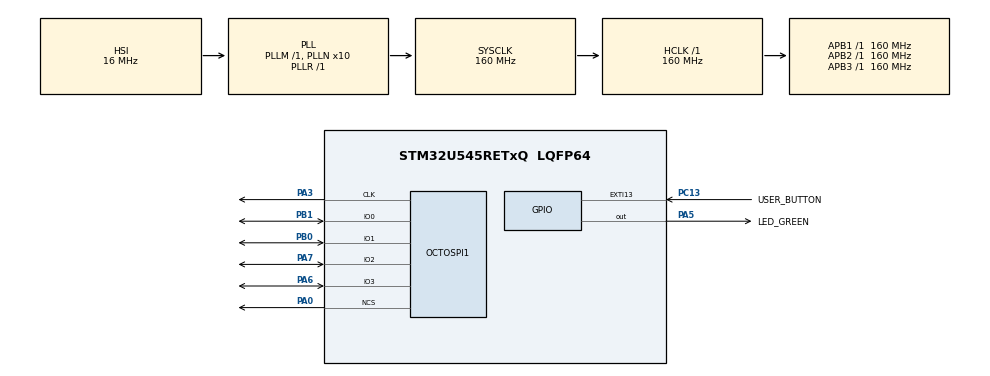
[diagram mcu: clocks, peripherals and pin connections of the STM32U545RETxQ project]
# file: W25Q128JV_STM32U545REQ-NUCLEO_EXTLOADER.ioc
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CORTEX_M33_NS.userName=CORTEX_M33
Mcu.Family=STM32U5
Mcu.Name=STM32U545RETxQ
Mcu.Package=LQFP64
NVIC.PriorityGroup=NVIC_PRIORITYGROUP_4
OCTOSPI1.ChipSelectBoundary=0
OCTOSPI1.ChipSelectHighTime=1
OCTOSPI1.ClockPrescaler=159
OCTOSPI1.DelayHoldQuarterCycle=HAL_OSPI_DHQC_DISABLE
OCTOSPI1.DeviceSize=24
OCTOSPI1.FifoThreshold=1
PA0.Mode=quad_mode
PA0.Signal=OCTOSPI1_NCS
PA13\ (JTMS/SWDIO).Mode=Serial_Wire
PA13\ (JTMS/SWDIO).Signal=DEBUG_JTMS-SWDIO
PA14\ (JTCK/SWCLK).Mode=Serial_Wire
PA14\ (JTCK/SWCLK).Signal=DEBUG_JTCK-SWCLK
PA3.Mode=quad_mode
PA3.Signal=OCTOSPI1_CLK
PA5.GPIO_Label=LED_GREEN
PA5.GPIO_PuPd=GPIO_PULLUP
PA5.GPIO_Speed=GPIO_SPEED_FREQ_HIGH
PA5.Signal=GPIO_Output
PA6.Mode=quad_mode
PA6.Signal=OCTOSPI1_IO3
PA7.Mode=quad_mode
PA7.Signal=OCTOSPI1_IO2
PB0.Mode=quad_mode
PB0.Signal=OCTOSPI1_IO1
PB1.Mode=quad_mode
PB1.Signal=OCTOSPI1_IO0
PC13.GPIO_Label=USER_BUTTON
PC13.GPIO_ModeDefaultEXTI=GPIO_MODE_IT_FALLING
PC13.Signal=GPXTI13
PC14-OSC32_IN\ (PC14).Mode=LSE-External-Oscillator
PC14-OSC32_IN\ (PC14).Signal=RCC_OSC32_IN
PC15-OSC32_OUT\ (PC15).Mode=LSE-External-Oscillator
PC15-OSC32_OUT\ (PC15).Signal=RCC_OSC32_OUT
PWR.PowerMode=PWR_SMPS_SUPPLY
ProjectManager.HeapSize=0x200
ProjectManager.StackSize=0x400
ProjectManager.TargetToolchain=STM32CubeIDE
RCC.ADCCLockSelection=RCC_ADCDACCLKSOURCE_PLL2
RCC.ADCFreq_Value=160000000
RCC.AHBFreq_Value=160000000
RCC.APB1Freq_Value=160000000
RCC.APB1TimFreq_Value=160000000
RCC.APB2Freq_Value=160000000
RCC.APB2TimFreq_Value=160000000
RCC.APB3Freq_Value=160000000
RCC.CortexFreq_Value=160000000
RCC.DACCLockSelectionVirtual=RCC_DAC1CLKSOURCE_LSI
RCC.DACCLockSelectionVirtualString=RCC_DAC1CLKSOURCE_LSI
RCC.EPOD_VALUE=16000000
RCC.HCLKFreq_Value=160000000
RCC.HSE_VALUE=16000000
RCC.HSI48_VALUE=48000000
RCC.HSI_VALUE=16000000
RCC.LSIDIV_VALUE=32000
RCC.MSI_VALUE=4000000
RCC.OCTOSPIMCLockSelection=RCC_OSPICLKSOURCE_PLL1
RCC.PLL1Q=1
RCC.PLL1R=1
RCC.PLL2FRACN=0
RCC.PLL2N=10
RCC.PLL2R=1
RCC.PLL2Source=RCC_PLLSOURCE_HSI
RCC.PLL3FRACN=0
RCC.PLL3M=12
RCC.PLL3Source=RCC_PLLSOURCE_HSI
RCC.PLLFRACN=0
RCC.PLLN=10
RCC.PLLSourceVirtual=RCC_PLLSOURCE_HSI
RCC.SYSCLKFreq_VALUE=160000000
RCC.SYSCLKSource=RCC_SYSCLKSOURCE_PLLCLK
RCC.USBFreq_Value=48000000
RCC.VCOOutputFreq_Value=160000000
VP_PWR_VS_DBSignals.Mode=DisableDeadBatterySignals
VP_PWR_VS_LPOM.Mode=PowerOptimisation
VP_PWR_VS_SECSignals.Mode=Security/Privilege
board=NUCLEO-U545RE-Q

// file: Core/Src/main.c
/* USER CODE BEGIN Header */
/**
  ******************************************************************************
  * @file           : main.c
  * @brief          : Main program body
  ******************************************************************************
  * @attention
  *
  * Copyright (c) 2025 STMicroelectronics.
  * All rights reserved.
  *
  * This software is licensed under terms that can be found in the LICENSE file
  * in the root directory of this software component.
  * If no LICENSE file comes with this software, it is provided AS-IS.
  *
  ******************************************************************************
  */
/* USER CODE END Header */
#include "main.h"
#include "octospi.h"
#include "gpio.h"

void SystemClock_Config(void);
static void SystemPower_Config(void);

int main(void)
{
  /* USER CODE BEGIN 1 */
  /* This main() entry point is used by the original linker script for
   * testing purposes, but not extloader.ld, which is the actual app! */
  /* USER CODE END 1 */

  /* MCU Configuration--------------------------------------------------------*/

  /* Reset of all peripherals, Initializes the Flash interface and the Systick. */
  HAL_Init();

  /* Configure the system clock */
  SystemClock_Config();

  /* Configure the System Power */
  SystemPower_Config();

  /* Initialize all configured peripherals */
  MX_GPIO_Init();
  MX_OCTOSPI1_Init();

  /* Infinite loop */
  while (1)
  {

  }
}

void SystemClock_Config(void)
{
  RCC_OscInitTypeDef RCC_OscInitStruct = {0};
  RCC_ClkInitTypeDef RCC_ClkInitStruct = {0};

  /** Configure the main internal regulator output voltage
  */
  if (HAL_PWREx_ControlVoltageScaling(PWR_REGULATOR_VOLTAGE_SCALE1) != HAL_OK)
  {
    Error_Handler();
  }

  /** Initializes the CPU, AHB and APB buses clocks
  */
  RCC_OscInitStruct.OscillatorType = RCC_OSCILLATORTYPE_HSI;
  RCC_OscInitStruct.HSIState = RCC_HSI_ON;
  RCC_OscInitStruct.HSICalibrationValue = RCC_HSICALIBRATION_DEFAULT;
  RCC_OscInitStruct.PLL.PLLState = RCC_PLL_ON;
  RCC_OscInitStruct.PLL.PLLSource = RCC_PLLSOURCE_HSI;
  RCC_OscInitStruct.PLL.PLLMBOOST = RCC_PLLMBOOST_DIV1;
  RCC_OscInitStruct.PLL.PLLM = 1;
  RCC_OscInitStruct.PLL.PLLN = 10;
  RCC_OscInitStruct.PLL.PLLP = 2;
  RCC_OscInitStruct.PLL.PLLQ = 1;
  RCC_OscInitStruct.PLL.PLLR = 1;
  RCC_OscInitStruct.PLL.PLLRGE = RCC_PLLVCIRANGE_1;
  RCC_OscInitStruct.PLL.PLLFRACN = 0;
  if (HAL_RCC_OscConfig(&RCC_OscInitStruct) != HAL_OK)
  {
    Error_Handler();
  }

  /** Initializes the CPU, AHB and APB buses clocks
  */
  RCC_ClkInitStruct.ClockType = RCC_CLOCKTYPE_HCLK|RCC_CLOCKTYPE_SYSCLK
                              |RCC_CLOCKTYPE_PCLK1|RCC_CLOCKTYPE_PCLK2
                              |RCC_CLOCKTYPE_PCLK3;
  RCC_ClkInitStruct.SYSCLKSource = RCC_SYSCLKSOURCE_PLLCLK;
  RCC_ClkInitStruct.AHBCLKDivider = RCC_SYSCLK_DIV1;
  RCC_ClkInitStruct.APB1CLKDivider = RCC_HCLK_DIV1;
  RCC_ClkInitStruct.APB2CLKDivider = RCC_HCLK_DIV1;
  RCC_ClkInitStruct.APB3CLKDivider = RCC_HCLK_DIV1;

  if (HAL_RCC_ClockConfig(&RCC_ClkInitStruct, FLASH_LATENCY_4) != HAL_OK)
  {
    Error_Handler();
  }
}

/**
  * @brief Power Configuration
  * @retval None
  */
static void SystemPower_Config(void)
{

  /*
   * Switch to SMPS regulator instead of LDO
   */
  if (HAL_PWREx_ConfigSupply(PWR_SMPS_SUPPLY) != HAL_OK)
  {
    Error_Handler();
  }
}

void Error_Handler(void)
{
  __disable_irq();
  while (1)
  {
  }
}
